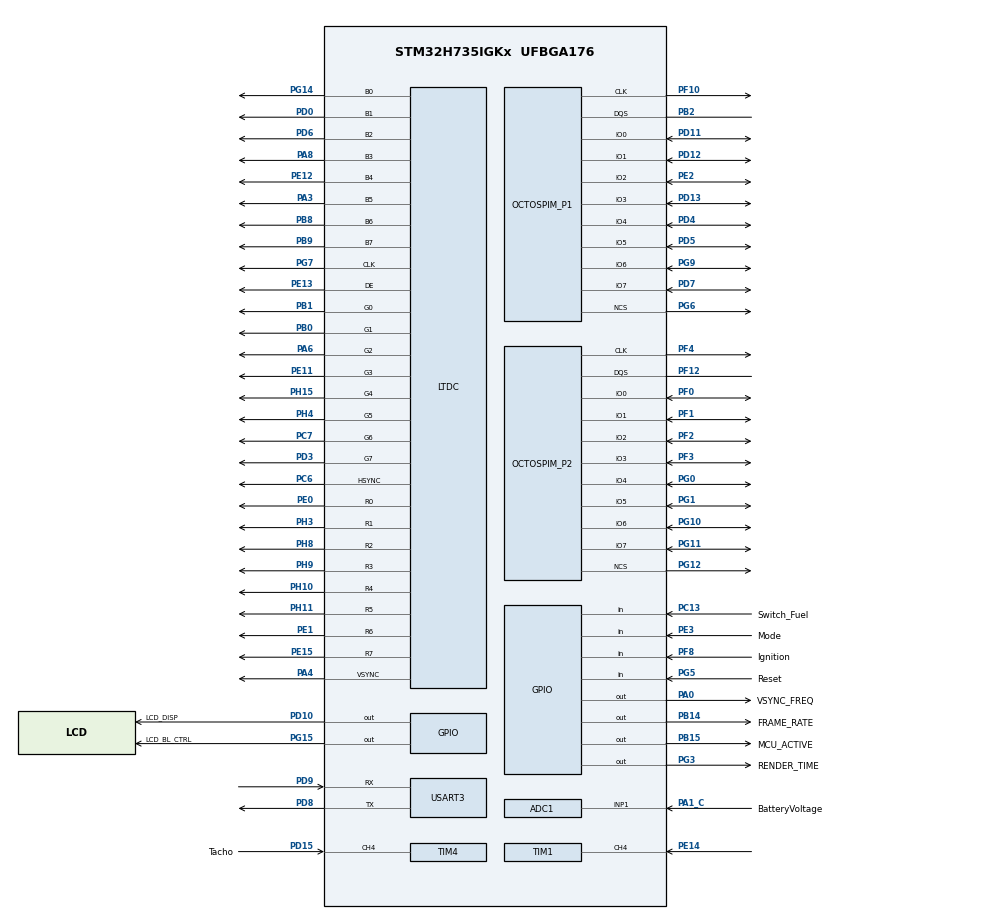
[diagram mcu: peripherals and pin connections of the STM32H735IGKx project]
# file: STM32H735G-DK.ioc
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ADC1.Channel-0\#ChannelRegularConversion=ADC_CHANNEL_1
ADC1.ClockPrescaler=ADC_CLOCK_SYNC_PCLK_DIV4
ADC1.NbrOfConversionFlag=1
ADC1.OffsetNumber-0\#ChannelRegularConversion=ADC_OFFSET_NONE
ADC1.OffsetSignedSaturation-0\#ChannelRegularConversion=DISABLE
ADC1.Rank-0\#ChannelRegularConversion=1
ADC1.Resolution=ADC_RESOLUTION_12B
ADC1.SamplingTime-0\#ChannelRegularConversion=ADC_SAMPLETIME_1CYCLE_5
ADC1.master=1
CORTEX_M7.AccessPermission-Cortex_Memory_Protection_Unit_Region0_Settings=MPU_REGION_FULL_ACCESS
CORTEX_M7.AccessPermission-Cortex_Memory_Protection_Unit_Region2_Settings=MPU_REGION_FULL_ACCESS
CORTEX_M7.AccessPermission-Cortex_Memory_Protection_Unit_Region4_Settings=MPU_REGION_FULL_ACCESS
CORTEX_M7.BaseAddress-Cortex_Memory_Protection_Unit_Region0_Settings=0x24000000
CORTEX_M7.BaseAddress-Cortex_Memory_Protection_Unit_Region1_Settings=0x70000000
CORTEX_M7.BaseAddress-Cortex_Memory_Protection_Unit_Region2_Settings=0x70000000
CORTEX_M7.BaseAddress-Cortex_Memory_Protection_Unit_Region3_Settings=0x90000000
CORTEX_M7.BaseAddress-Cortex_Memory_Protection_Unit_Region4_Settings=0x90000000
CORTEX_M7.CPU_DCache=Enabled
CORTEX_M7.CPU_ICache=Enabled
CORTEX_M7.DisableExec-Cortex_Memory_Protection_Unit_Region0_Settings=MPU_INSTRUCTION_ACCESS_DISABLE
CORTEX_M7.DisableExec-Cortex_Memory_Protection_Unit_Region1_Settings=MPU_INSTRUCTION_ACCESS_DISABLE
CORTEX_M7.DisableExec-Cortex_Memory_Protection_Unit_Region2_Settings=MPU_INSTRUCTION_ACCESS_DISABLE
CORTEX_M7.DisableExec-Cortex_Memory_Protection_Unit_Region3_Settings=MPU_INSTRUCTION_ACCESS_DISABLE
CORTEX_M7.DisableExec-Cortex_Memory_Protection_Unit_Region4_Settings=MPU_INSTRUCTION_ACCESS_DISABLE
CORTEX_M7.Enable-Cortex_Memory_Protection_Unit_Region0_Settings=MPU_REGION_ENABLE
CORTEX_M7.Enable-Cortex_Memory_Protection_Unit_Region1_Settings=MPU_REGION_ENABLE
CORTEX_M7.Enable-Cortex_Memory_Protection_Unit_Region2_Settings=MPU_REGION_ENABLE
CORTEX_M7.Enable-Cortex_Memory_Protection_Unit_Region3_Settings=MPU_REGION_ENABLE
CORTEX_M7.Enable-Cortex_Memory_Protection_Unit_Region4_Settings=MPU_REGION_ENABLE
CORTEX_M7.IsBufferable-Cortex_Memory_Protection_Unit_Region0_Settings=MPU_ACCESS_BUFFERABLE
CORTEX_M7.IsBufferable-Cortex_Memory_Protection_Unit_Region2_Settings=MPU_ACCESS_BUFFERABLE
CORTEX_M7.IsCacheable-Cortex_Memory_Protection_Unit_Region0_Settings=MPU_ACCESS_CACHEABLE
CORTEX_M7.IsCacheable-Cortex_Memory_Protection_Unit_Region2_Settings=MPU_ACCESS_CACHEABLE
CORTEX_M7.IsCacheable-Cortex_Memory_Protection_Unit_Region4_Settings=MPU_ACCESS_CACHEABLE
CORTEX_M7.MPU_Control=MPU_PRIVILEGED_DEFAULT
CORTEX_M7.Size-Cortex_Memory_Protection_Unit_Region0_Settings=MPU_REGION_SIZE_512KB
CORTEX_M7.Size-Cortex_Memory_Protection_Unit_Region1_Settings=MPU_REGION_SIZE_512MB
CORTEX_M7.Size-Cortex_Memory_Protection_Unit_Region2_Settings=MPU_REGION_SIZE_8MB
CORTEX_M7.Size-Cortex_Memory_Protection_Unit_Region3_Settings=MPU_REGION_SIZE_512MB
CORTEX_M7.Size-Cortex_Memory_Protection_Unit_Region4_Settings=MPU_REGION_SIZE_64MB
CORTEX_M7.default_mode_Activation=1
DMA2D.ColorMode=DMA2D_OUTPUT_RGB888
DMA2D.Mode=DMA2D_R2M
FREERTOS.Tasks01=defaultTask,24,128,StartDefaultTask,Default,NULL,Static,defaultTaskBuffer,defaultTaskControlBlock;TouchGFXTask,24,1024,TouchGFX_Task,As external,NULL,Dynamic,NULL,NULL;videoTask,8,1024,videoTaskFunc,As external,NULL,Static,videoTaskBuffer,videoTaskControlBlock;WatchdogService,8,128,WDG_SRVC_Task,Default,NULL,Static,WatchdogServiceBuffer,WatchdogServiceControlBlock;DigitalDebounce,8,128,DigitalDebounce_Task,Default,NULL,Static,DigitalDebounceBuffer,DigitalDebounceControlBlock;State_Manager,8,128,State_Machine,Default,NULL,Static,State_ManagerBuffer,State_ManagerControlBlock;Odometer,24,128,Odo_Task,Default,NULL,Static,OdometerBuffer,OdometerControlBlock;speedometer,24,128,speedo_Task,Default,NULL,Static,speedometerBuffer,speedometerControlBlock;Tachometer,24,128,Tacho_Task,Default,NULL,Static,TachometerBuffer,TachometerControlBlock
FREERTOS.configTOTAL_HEAP_SIZE=75000
FREERTOS.configUSE_APPLICATION_TASK_TAG=1
FREERTOS.configUSE_IDLE_HOOK=1
FREERTOS.configUSE_NEWLIB_REENTRANT=1
LIBJPEG.RGB_ORDERING=BGR
LTDC.ActiveH=272
LTDC.ActiveW=480
LTDC.Alpha_L0=255
LTDC.FBStartAdress_L0=0x70000000
LTDC.FBStartAdress_L1=0x70000000
LTDC.HBP=13
LTDC.HFP=32
LTDC.HSync=41
LTDC.ImageHeight_L0=272
LTDC.ImageWidth_L0=480
LTDC.Layers=0
LTDC.PixelFormat_L0=LTDC_PIXEL_FORMAT_RGB888
LTDC.VSync=10
LTDC.WindowX1_L0=480
LTDC.WindowY1_L0=272
Mcu.Family=STM32H7
Mcu.Name=STM32H735IGKx
Mcu.Package=UFBGA176
NVIC.DMA2D_IRQn=true\:5\:0\:true\:false\:true\:false\:true\:true\:true
NVIC.LTDC_IRQn=true\:5\:0\:true\:false\:true\:false\:true\:true\:true
NVIC.PriorityGroup=NVIC_PRIORITYGROUP_4
NVIC.TIM1_CC_IRQn=true\:5\:0\:false\:false\:true\:true\:true\:true\:true
NVIC.TIM4_IRQn=true\:5\:0\:false\:false\:true\:true\:true\:true\:true
NVIC.TIM6_DAC_IRQn=true\:0\:0\:false\:false\:true\:false\:false\:true\:true
NVIC.TimeBase=TIM6_DAC_IRQn
NVIC.TimeBaseIP=TIM6
OCTOSPI1.ChipSelectBoundary=0
OCTOSPI1.ChipSelectHighTime=2
OCTOSPI1.ClockPrescaler=2
OCTOSPI1.FifoThreshold=4
OCTOSPI1.MemoryType=HAL_OSPI_MEMTYPE_MACRONIX
OCTOSPI2.AccessTime=6
OCTOSPI2.ChipSelectBoundary=23
OCTOSPI2.ChipSelectHighTime=4
OCTOSPI2.ClkChipSelectHighTime=0
OCTOSPI2.ClockPrescaler=2
OCTOSPI2.DelayBlockBypass=HAL_OSPI_DELAY_BLOCK_USED
OCTOSPI2.DelayHoldQuarterCycle=HAL_OSPI_DHQC_ENABLE
OCTOSPI2.DeviceSize=24
OCTOSPI2.FifoThreshold=4
OCTOSPI2.LatencyMode=HAL_OSPI_FIXED_LATENCY
OCTOSPI2.RWRecoveryTime=3
OCTOSPI2.Refresh=400
OCTOSPI2.WriteZeroLatency=HAL_OSPI_LATENCY_ON_WRITE
PA0.GPIO_Label=VSYNC_FREQ
PA0.GPIO_Speed=GPIO_SPEED_FREQ_VERY_HIGH
PA0.Signal=GPIO_Output
PA1_C.GPIO_Label=BatteryVoltage
PA1_C.Signal=ADCx_INP1
PA3.GPIO_Speed=GPIO_SPEED_FREQ_VERY_HIGH
PA3.Mode=RGB888
PA3.Signal=LTDC_B5
PA4.GPIO_Speed=GPIO_SPEED_FREQ_VERY_HIGH
PA4.Mode=RGB888
PA4.Signal=LTDC_VSYNC
PA6.GPIO_Speed=GPIO_SPEED_FREQ_VERY_HIGH
PA6.Mode=RGB888
PA6.Signal=LTDC_G2
PA8.GPIO_Speed=GPIO_SPEED_FREQ_VERY_HIGH
PA8.Mode=RGB888
PA8.Signal=LTDC_B3
PB0.GPIO_Speed=GPIO_SPEED_FREQ_VERY_HIGH
PB0.Mode=RGB888
PB0.Signal=LTDC_G1
PB1.GPIO_Speed=GPIO_SPEED_FREQ_VERY_HIGH
PB1.Mode=RGB888
PB1.Signal=LTDC_G0
PB14.GPIO_Label=FRAME_RATE
PB14.GPIO_Speed=GPIO_SPEED_FREQ_VERY_HIGH
PB14.Signal=GPIO_Output
PB15.GPIO_Label=MCU_ACTIVE
PB15.GPIO_Speed=GPIO_SPEED_FREQ_VERY_HIGH
PB15.Signal=GPIO_Output
PB2.Mode=OCTOSPI1_Port1_DQS
PB2.Signal=OCTOSPIM_P1_DQS
PB8.GPIO_Speed=GPIO_SPEED_FREQ_VERY_HIGH
PB8.Mode=RGB888
PB8.Signal=LTDC_B6
PB9.GPIO_Speed=GPIO_SPEED_FREQ_VERY_HIGH
PB9.Mode=RGB888
PB9.Signal=LTDC_B7
PC13.GPIO_Label=Switch_Fuel
PC13.GPIO_PuPd=GPIO_PULLDOWN
PC13.Signal=GPIO_Input
PC6.GPIO_Speed=GPIO_SPEED_FREQ_VERY_HIGH
PC6.Mode=RGB888
PC6.Signal=LTDC_HSYNC
PC7.GPIO_Speed=GPIO_SPEED_FREQ_VERY_HIGH
PC7.Mode=RGB888
PC7.Signal=LTDC_G6
PD0.GPIO_Speed=GPIO_SPEED_FREQ_VERY_HIGH
PD0.Mode=RGB888
PD0.Signal=LTDC_B1
PD10.GPIO_Label=LCD_DISP
PD10.GPIO_PuPd=GPIO_NOPULL
PD10.GPIO_Speed=GPIO_SPEED_FREQ_LOW
PD10.PinState=GPIO_PIN_RESET
PD10.Signal=GPIO_Output
PD11.Mode=OCTOSPI1_IOL_Port1L
PD11.Signal=OCTOSPIM_P1_IO0
PD12.Mode=OCTOSPI1_IOL_Port1L
PD12.Signal=OCTOSPIM_P1_IO1
PD13.Mode=OCTOSPI1_IOL_Port1L
PD13.Signal=OCTOSPIM_P1_IO3
PD15.GPIO_Label=Tacho
PD15.Signal=S_TIM4_CH4
PD3.GPIO_Speed=GPIO_SPEED_FREQ_VERY_HIGH
PD3.Mode=RGB888
PD3.Signal=LTDC_G7
PD4.Mode=OCTOSPI1_IOH_Port1H
PD4.Signal=OCTOSPIM_P1_IO4
PD5.Mode=OCTOSPI1_IOH_Port1H
PD5.Signal=OCTOSPIM_P1_IO5
PD6.GPIO_Speed=GPIO_SPEED_FREQ_VERY_HIGH
PD6.Mode=RGB888
PD6.Signal=LTDC_B2
PD7.Mode=OCTOSPI1_IOH_Port1H
PD7.Signal=OCTOSPIM_P1_IO7
PD8.Mode=Asynchronous
PD8.Signal=USART3_TX
PD9.Mode=Asynchronous
PD9.Signal=USART3_RX
PE0.GPIO_Speed=GPIO_SPEED_FREQ_VERY_HIGH
PE0.Mode=RGB888
PE0.Signal=LTDC_R0
PE1.GPIO_Speed=GPIO_SPEED_FREQ_VERY_HIGH
PE1.Mode=RGB888
PE1.Signal=LTDC_R6
PE11.GPIO_Speed=GPIO_SPEED_FREQ_VERY_HIGH
PE11.Mode=RGB888
PE11.Signal=LTDC_G3
PE12.GPIO_Speed=GPIO_SPEED_FREQ_VERY_HIGH
PE12.Mode=RGB888
PE12.Signal=LTDC_B4
PE13.GPIO_Speed=GPIO_SPEED_FREQ_VERY_HIGH
PE13.Mode=RGB888
PE13.Signal=LTDC_DE
PE14.GPIO_PuPd=GPIO_PULLDOWN
PE14.Signal=S_TIM1_CH4
PE15.GPIO_Speed=GPIO_SPEED_FREQ_VERY_HIGH
PE15.Mode=RGB888
PE15.Signal=LTDC_R7
PE2.Mode=OCTOSPI1_IOL_Port1L
PE2.Signal=OCTOSPIM_P1_IO2
PE3.GPIO_Label=Mode
PE3.GPIO_PuPd=GPIO_PULLUP
PE3.Signal=GPIO_Input
PF0.Mode=OCTOSPI2_IOL_Port2L
PF0.Signal=OCTOSPIM_P2_IO0
PF1.Mode=OCTOSPI2_IOL_Port2L
PF1.Signal=OCTOSPIM_P2_IO1
PF10.Mode=O1_P1_CLK
PF10.Signal=OCTOSPIM_P1_CLK
PF12.Mode=OCTOSPI2_Port2_DQS
PF12.Signal=OCTOSPIM_P2_DQS
PF2.Mode=OCTOSPI2_IOL_Port2L
PF2.Signal=OCTOSPIM_P2_IO2
PF3.Mode=OCTOSPI2_IOL_Port2L
PF3.Signal=OCTOSPIM_P2_IO3
PF4.Mode=O2_P2_CLK
PF4.Signal=OCTOSPIM_P2_CLK
PF6.Signal=FDCAN3_RX
PF8.GPIO_Label=Ignition
PF8.GPIO_PuPd=GPIO_PULLUP
PF8.Signal=GPIO_Input
PG0.Mode=OCTOSPI2_IOH_Port2H
PG0.Signal=OCTOSPIM_P2_IO4
PG1.Mode=OCTOSPI2_IOH_Port2H
PG1.Signal=OCTOSPIM_P2_IO5
PG10.Mode=OCTOSPI2_IOH_Port2H
PG10.Signal=OCTOSPIM_P2_IO6
PG11.Mode=OCTOSPI2_IOH_Port2H
PG11.Signal=OCTOSPIM_P2_IO7
PG12.Mode=OCTOSPI2_Port2_NCS
PG12.Signal=OCTOSPIM_P2_NCS
PG14.GPIO_Speed=GPIO_SPEED_FREQ_VERY_HIGH
PG14.Mode=RGB888
PG14.Signal=LTDC_B0
PG15.GPIO_Label=LCD_BL_CTRL
PG15.Signal=GPIO_Output
PG3.GPIO_Label=RENDER_TIME
PG3.GPIO_Speed=GPIO_SPEED_FREQ_VERY_HIGH
PG3.Signal=GPIO_Output
PG5.GPIO_Label=Reset
PG5.GPIO_PuPd=GPIO_PULLUP
PG5.Signal=GPIO_Input
PG6.Mode=OCTOSPI1_Port1_NCS
PG6.Signal=OCTOSPIM_P1_NCS
PG7.GPIO_Speed=GPIO_SPEED_FREQ_VERY_HIGH
PG7.Mode=RGB888
PG7.Signal=LTDC_CLK
PG9.Mode=OCTOSPI1_IOH_Port1H
PG9.Signal=OCTOSPIM_P1_IO6
PH0-OSC_IN.Mode=HSE-External-Oscillator
PH0-OSC_IN.Signal=RCC_OSC_IN
PH1-OSC_OUT.Mode=HSE-External-Oscillator
PH1-OSC_OUT.Signal=RCC_OSC_OUT
PH10.GPIO_Speed=GPIO_SPEED_FREQ_VERY_HIGH
PH10.Mode=RGB888
PH10.Signal=LTDC_R4
PH11.GPIO_Speed=GPIO_SPEED_FREQ_VERY_HIGH
PH11.Mode=RGB888
PH11.Signal=LTDC_R5
PH15.GPIO_Speed=GPIO_SPEED_FREQ_VERY_HIGH
PH15.Mode=RGB888
PH15.Signal=LTDC_G4
PH3.GPIO_Speed=GPIO_SPEED_FREQ_VERY_HIGH
PH3.Mode=RGB888
PH3.Signal=LTDC_R1
PH4.GPIO_Speed=GPIO_SPEED_FREQ_VERY_HIGH
PH4.Mode=RGB888
PH4.Signal=LTDC_G5
PH8.GPIO_Speed=GPIO_SPEED_FREQ_VERY_HIGH
PH8.Mode=RGB888
PH8.Signal=LTDC_R2
PH9.GPIO_Speed=GPIO_SPEED_FREQ_VERY_HIGH
PH9.Mode=RGB888
PH9.Signal=LTDC_R3
ProjectManager.HeapSize=0x1000
ProjectManager.StackSize=0x1000
ProjectManager.TargetToolchain=STM32CubeIDE
RCC.ADCFreq_Value=200000000
RCC.APB1Freq_Value=137500000
RCC.APB2Freq_Value=137500000
RCC.APB3Freq_Value=137500000
RCC.APB4Freq_Value=137500000
RCC.CortexFreq_Value=550000000
RCC.D1PPRE=RCC_APB3_DIV2
RCC.D2PPRE1=RCC_APB1_DIV2
RCC.D2PPRE2=RCC_APB2_DIV2
RCC.D3PPRE=RCC_APB4_DIV2
RCC.DIVM1=2
RCC.DIVM2=5
RCC.DIVM3=25
RCC.DIVN1=44
RCC.DIVN2=80
RCC.DIVN3=288
RCC.DIVP1=1
RCC.DIVR3=30
RCC.HCLKFreq_Value=275000000
RCC.HPRE=RCC_HCLK_DIV2
RCC.PLL2FRACN=0
RCC.PLLFRACN=0
RCC.PLLSourceVirtual=RCC_PLLSOURCE_HSE
RCC.QSPICLockSelection=RCC_OSPICLKSOURCE_PLL2
RCC.SYSCLKFreq_VALUE=550000000
RCC.SYSCLKSource=RCC_SYSCLKSOURCE_PLLCLK
RCC.SupplySource=PWR_DIRECT_SMPS_SUPPLY
RCC.USBFreq_Value=275000000
SH.ADCx_INP1.0=ADC1_INP1,IN1-Single-Ended
SH.S_TIM1_CH4.0=TIM1_CH4,Input_Capture4_from_TI4
SH.S_TIM4_CH4.0=TIM4_CH4,Input_Capture4_from_TI4
STMicroelectronics.X-CUBE-TOUCHGFX.4.23.1.ApplicationCcGraphicsJjApplication=TouchGFXOoGenerator
STMicroelectronics.X-CUBE-TOUCHGFX.4.23.1.tgfx_address1=0x70000000
STMicroelectronics.X-CUBE-TOUCHGFX.4.23.1.tgfx_address2=0x70060000
STMicroelectronics.X-CUBE-TOUCHGFX.4.23.1.tgfx_buffering_strategy=Double
STMicroelectronics.X-CUBE-TOUCHGFX.4.23.1.tgfx_display_interface=disp_ltdc
STMicroelectronics.X-CUBE-TOUCHGFX.4.23.1.tgfx_hardware_accelerator=dma_2d
STMicroelectronics.X-CUBE-TOUCHGFX.4.23.1.tgfx_location=Allocate
STMicroelectronics.X-CUBE-TOUCHGFX.4.23.1.tgfx_vector_fonts=Enabled
STMicroelectronics.X-CUBE-TOUCHGFX.4.23.1.tgfx_vector_rendering=Software
STMicroelectronics.X-CUBE-TOUCHGFX.4.23.1.tgfx_video=Software
STMicroelectronics.X-CUBE-TOUCHGFX.4.23.1.tgfx_video_buffer_format=RGB888\:3
STMicroelectronics.X-CUBE-TOUCHGFX.4.23.1.tgfx_video_height=272
STMicroelectronics.X-CUBE-TOUCHGFX.4.23.1.tgfx_video_strategy=1
STMicroelectronics.X-CUBE-TOUCHGFX.4.23.1.tgfx_video_width=480
STMicroelectronics.X-CUBE-TOUCHGFX.4.23.1.tgfx_vsync=vsync_ltdc
TIM1.Channel-Input_Capture4_from_TI4=TIM_CHANNEL_4
TIM4.Channel-Input_Capture4_from_TI4=TIM_CHANNEL_4
USART3.Parity=PARITY_NONE
USART3.VirtualMode-Asynchronous=VM_ASYNC
VP_CRC_VS_CRC.Mode=CRC_Activate
VP_DMA2D_VS_DMA2D.Mode=DMA2D_Activate
VP_FREERTOS_VS_CMSIS_V2.Mode=CMSIS_V2
VP_LIBJPEG_VS_JPEGLIB.Mode=Enabled
VP_OCTOSPI1_VS_octo.Mode=octo_mode
VP_OCTOSPI2_VS_octo.Mode=hyperbus_mode
VP_RTC_VS_RTC_Activate.Mode=RTC_Enabled
VP_RTC_VS_RTC_Calendar.Mode=RTC_Calendar
VP_STMicroelectronics.X-CUBE-TOUCHGFX_VS_GraphicsJjApplication_4.23.1.Mode=GraphicsJjApplication
VP_SYS_VS_tim6.Mode=TIM6
VP_TIM1_VS_ClockSourceINT.Mode=Internal
VP_WWDG1_VS_WWDG.Mode=WWDG_Activate
WWDG1.Counter=0x7F
WWDG1.Prescaler=WWDG_PRESCALER_128
WWDG1.Window=0x50
board=custom

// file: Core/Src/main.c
/* USER CODE BEGIN Header */
/**
  ******************************************************************************
  * @file           : main.c
  * @brief          : Main program body
  ******************************************************************************
  * @attention
  *
  * <h2><center>&copy; Copyright (c) 2020 STMicroelectronics.
  * All rights reserved.</center></h2>
  *
  * This software component is licensed by ST under Ultimate Liberty license
  * SLA0044, the "License"; You may not use this file except in compliance with
  * the License. You may obtain a copy of the License at:
  *                             www.st.com/SLA0044
  *
  ******************************************************************************
  */
/* USER CODE END Header */
#include "main.h"
#include "cmsis_os.h"
#include "libjpeg.h"
#include "app_touchgfx.h"

/* USER CODE BEGIN Includes */
#include "stm32h735g_discovery_ospi.h"
#include "stm32h7xx_hal_ospi.h"
#include "smHandler.h"
#include "digital_debounce.h"
#include "Tachometer_App.h"
#include "Odometer_App.h"
#include "speedometer_App.h"
#include "eeprom_emul.h"
#include <touchgfx/hal/Config.hpp>

/* USER CODE END Includes */

typedef StaticTask_t osStaticThreadDef_t;
/* USER CODE BEGIN PTD */
#ifdef __GNUC__
/* With GCC, small printf (option LD Linker->Libraries->Small printf
   set to 'Yes') calls __io_putchar() */
#define PUTCHAR_PROTOTYPE int __io_putchar(int ch)
#else
#define PUTCHAR_PROTOTYPE int fputc(int ch, FILE *f)
#endif /* __GNUC__ */
/* USER CODE END PTD */

ADC_HandleTypeDef hadc1;

CRC_HandleTypeDef hcrc;

DMA2D_HandleTypeDef hdma2d;

LTDC_HandleTypeDef hltdc;

OSPI_HandleTypeDef hospi1;
OSPI_HandleTypeDef hospi2;

RTC_HandleTypeDef hrtc;

TIM_HandleTypeDef htim1;
TIM_HandleTypeDef htim4;

UART_HandleTypeDef huart3;

WWDG_HandleTypeDef hwwdg1;

/* Definitions for defaultTask */
osThreadId_t defaultTaskHandle;
uint32_t defaultTaskBuffer[ 128 ];
osStaticThreadDef_t defaultTaskControlBlock;
const osThreadAttr_t defaultTask_attributes = {
  .name = "defaultTask",
  .cb_mem = &defaultTaskControlBlock,
  .cb_size = sizeof(defaultTaskControlBlock),
  .stack_mem = &defaultTaskBuffer[0],
  .stack_size = sizeof(defaultTaskBuffer),
  .priority = (osPriority_t) osPriorityNormal,
};
/* Definitions for TouchGFXTask */
osThreadId_t TouchGFXTaskHandle;
const osThreadAttr_t TouchGFXTask_attributes = {
  .name = "TouchGFXTask",
  .stack_size = 1024 * 4,
  .priority = (osPriority_t) osPriorityNormal,
};
/* Definitions for videoTask */
osThreadId_t videoTaskHandle;
uint32_t videoTaskBuffer[ 1024 ];
osStaticThreadDef_t videoTaskControlBlock;
const osThreadAttr_t videoTask_attributes = {
  .name = "videoTask",
  .cb_mem = &videoTaskControlBlock,
  .cb_size = sizeof(videoTaskControlBlock),
  .stack_mem = &videoTaskBuffer[0],
  .stack_size = sizeof(videoTaskBuffer),
  .priority = (osPriority_t) osPriorityLow,
};
/* Definitions for WatchdogService */
osThreadId_t WatchdogServiceHandle;
uint32_t WatchdogServiceBuffer[ 128 ];
osStaticThreadDef_t WatchdogServiceControlBlock;
const osThreadAttr_t WatchdogService_attributes = {
  .name = "WatchdogService",
  .cb_mem = &WatchdogServiceControlBlock,
  .cb_size = sizeof(WatchdogServiceControlBlock),
  .stack_mem = &WatchdogServiceBuffer[0],
  .stack_size = sizeof(WatchdogServiceBuffer),
  .priority = (osPriority_t) osPriorityLow,
};
/* Definitions for DigitalDebounce */
osThreadId_t DigitalDebounceHandle;
uint32_t DigitalDebounceBuffer[ 4096*2 ];
osStaticThreadDef_t DigitalDebounceControlBlock;
const osThreadAttr_t DigitalDebounce_attributes = {
  .name = "DigitalDebounce",
  .cb_mem = &DigitalDebounceControlBlock,
  .cb_size = sizeof(DigitalDebounceControlBlock),
  .stack_mem = &DigitalDebounceBuffer[0],
  .stack_size = sizeof(DigitalDebounceBuffer),
  .priority = (osPriority_t) osPriorityNormal,
};
/* Definitions for State_Manager */
osThreadId_t State_ManagerHandle;
uint32_t State_ManagerBuffer[ 128 ];
osStaticThreadDef_t State_ManagerControlBlock;
const osThreadAttr_t State_Manager_attributes = {
  .name = "State_Manager",
  .cb_mem = &State_ManagerControlBlock,
  .cb_size = sizeof(State_ManagerControlBlock),
  .stack_mem = &State_ManagerBuffer[0],
  .stack_size = sizeof(State_ManagerBuffer),
  .priority = (osPriority_t) osPriorityLow,
};
/* Definitions for Odometer */
osThreadId_t OdometerHandle;
uint32_t OdometerBuffer[ 128 ];
osStaticThreadDef_t OdometerControlBlock;
const osThreadAttr_t Odometer_attributes = {
  .name = "Odometer",
  .cb_mem = &OdometerControlBlock,
  .cb_size = sizeof(OdometerControlBlock),
  .stack_mem = &OdometerBuffer[0],
  .stack_size = sizeof(OdometerBuffer),
  .priority = (osPriority_t) osPriorityNormal,
};
/* Definitions for speedometer */
osThreadId_t speedometerHandle;
uint32_t speedometerBuffer[ 128 ];
osStaticThreadDef_t speedometerControlBlock;
const osThreadAttr_t speedometer_attributes = {
  .name = "speedometer",
  .cb_mem = &speedometerControlBlock,
  .cb_size = sizeof(speedometerControlBlock),
  .stack_mem = &speedometerBuffer[0],
  .stack_size = sizeof(speedometerBuffer),
  .priority = (osPriority_t) osPriorityNormal,
};
/* Definitions for Tachometer */
osThreadId_t TachometerHandle;
uint32_t TachometerBuffer[ 128 ];
osStaticThreadDef_t TachometerControlBlock;
const osThreadAttr_t Tachometer_attributes = {
  .name = "Tachometer",
  .cb_mem = &TachometerControlBlock,
  .cb_size = sizeof(TachometerControlBlock),
  .stack_mem = &TachometerBuffer[0],
  .stack_size = sizeof(TachometerBuffer),
  .priority = (osPriority_t) osPriorityNormal,
};
/* USER CODE BEGIN PV */
/**
  * @brief  Retargets the C library printf function to the USART.
  * @param  None
  * @retval None
  */
PUTCHAR_PROTOTYPE
{
  /* Place your implementation of fputc here */
  /* e.g. write a character to the USART1 and Loop until the end of transmission */
  HAL_UART_Transmit(&huart3, (uint8_t *)&ch, 1, 0xFFFF);
  return ch;
}
/* USER CODE END PV */

void SystemClock_Config(void);
void PeriphCommonClock_Config(void);
static void MPU_Config(void);
static void MX_GPIO_Init(void);
static void MX_CRC_Init(void);
static void MX_DMA2D_Init(void);
static void MX_LTDC_Init(void);
static void MX_OCTOSPI1_Init(void);
static void MX_OCTOSPI2_Init(void);
static void MX_TIM1_Init(void);
static void MX_TIM4_Init(void);
static void MX_ADC1_Init(void);
static void MX_RTC_Init(void);
static void MX_WWDG1_Init(void);
static void MX_USART3_UART_Init(void);
void StartDefaultTask(void *argument);
extern void TouchGFX_Task(void *argument);
extern void videoTaskFunc(void *argument);
void WDG_SRVC_Task(void *argument);
void DigitalDebounce_Task(void *argument);
void State_Machine(void *argument);
void Odo_Task(void *argument);
void speedo_Task(void *argument);
void Tacho_Task(void *argument);

/* USER CODE BEGIN PFP */
static uint32_t TimeoutCalculation(uint32_t timevalue);
extern void vEE_Demo(void);
void Disp_imgDataHyperRAM_Init(void);
/* USER CODE END PFP */

/* USER CODE BEGIN 0 */
KEEP extern const unsigned char image_image_const[];
KEEP extern const unsigned char image_fuel_red_const[];
extern unsigned char ucImage_image_HypRam[(32640*12)];
extern unsigned char ucImage_fuel_red_HypRAM[160*12];

/* USER CODE END 0 */

int main(void)
{

  /* MPU Configuration--------------------------------------------------------*/
  MPU_Config();

  /* Enable the CPU Cache */

  /* Enable I-Cache---------------------------------------------------------*/
  SCB_EnableICache();

  /* Enable D-Cache---------------------------------------------------------*/
  SCB_EnableDCache();

  /* MCU Configuration--------------------------------------------------------*/

  /* Reset of all peripherals, Initializes the Flash interface and the Systick. */
  HAL_Init();

  /* Configure the system clock */
  SystemClock_Config();

/* Configure the peripherals common clocks */
  PeriphCommonClock_Config();

  /* Initialize all configured peripherals */

  MX_GPIO_Init();
  MX_CRC_Init();
  MX_DMA2D_Init();
  MX_LTDC_Init();
//  MX_OCTOSPI1_Init();
  MX_OCTOSPI2_Init();
  MX_LIBJPEG_Init();
  MX_TIM1_Init();
  MX_TIM4_Init();
  MX_ADC1_Init();
  MX_RTC_Init();
//  MX_WWDG1_Init();
  MX_USART3_UART_Init();
  MX_TouchGFX_Init();
  /* Call PreOsInit function */
  MX_TouchGFX_PreOSInit();

  /* USER CODE BEGIN 2 */

  State_Manager_init();
  vOdoInit();
  vSpeedoInit();

  if(HAL_TIM_IC_Start_IT(&htim1,TIM_CHANNEL_4)!=HAL_OK)
  {
	  Error_Handler();
  }
  if(HAL_TIM_IC_Start_IT(&htim4,TIM_CHANNEL_4)!=HAL_OK)
  {
	  Error_Handler();
  }

  vEE_Demo();
  Disp_imgDataHyperRAM_Init();

  /* USER CODE END 2 */

  /* Init scheduler */
  osKernelInitialize();

  /* Create the thread(s) */
  /* creation of defaultTask */
  defaultTaskHandle = osThreadNew(StartDefaultTask, NULL, &defaultTask_attributes);

  /* creation of TouchGFXTask */
  TouchGFXTaskHandle = osThreadNew(TouchGFX_Task, NULL, &TouchGFXTask_attributes);

  /* creation of videoTask */
  videoTaskHandle = osThreadNew(videoTaskFunc, NULL, &videoTask_attributes);

  /* creation of WatchdogService */
  WatchdogServiceHandle = osThreadNew(WDG_SRVC_Task, NULL, &WatchdogService_attributes);

  /* creation of DigitalDebounce */
  DigitalDebounceHandle = osThreadNew(DigitalDebounce_Task, NULL, &DigitalDebounce_attributes);

  /* creation of State_Manager */
  State_ManagerHandle = osThreadNew(State_Machine, NULL, &State_Manager_attributes);

  /* creation of Odometer */
  OdometerHandle = osThreadNew(Odo_Task, NULL, &Odometer_attributes);

  /* creation of speedometer */
  speedometerHandle = osThreadNew(speedo_Task, NULL, &speedometer_attributes);

  /* creation of Tachometer */
  TachometerHandle = osThreadNew(Tacho_Task, NULL, &Tachometer_attributes);

  /* Start scheduler */
  osKernelStart();

  /* We should never get here as control is now taken by the scheduler */

  /* Infinite loop */
  while (1)
  {

  }
}

void SystemClock_Config(void)
{
  RCC_OscInitTypeDef RCC_OscInitStruct = {0};
  RCC_ClkInitTypeDef RCC_ClkInitStruct = {0};

  /** Supply configuration update enable
  */
  HAL_PWREx_ConfigSupply(PWR_DIRECT_SMPS_SUPPLY);

  /** Configure the main internal regulator output voltage
  */
  __HAL_PWR_VOLTAGESCALING_CONFIG(PWR_REGULATOR_VOLTAGE_SCALE0);

  while(!__HAL_PWR_GET_FLAG(PWR_FLAG_VOSRDY)) {}
#if 0
  /** Initializes the RCC Oscillators according to the specified parameters
  * in the RCC_OscInitTypeDef structure.
  */
  RCC_OscInitStruct.OscillatorType = RCC_OSCILLATORTYPE_LSI|RCC_OSCILLATORTYPE_HSE;
  RCC_OscInitStruct.HSEState = RCC_HSE_ON;
  RCC_OscInitStruct.LSIState = RCC_LSI_ON;
  RCC_OscInitStruct.PLL.PLLState = RCC_PLL_ON;
  RCC_OscInitStruct.PLL.PLLSource = RCC_PLLSOURCE_HSE;
  RCC_OscInitStruct.PLL.PLLM = 2;
  RCC_OscInitStruct.PLL.PLLN = 44;
  RCC_OscInitStruct.PLL.PLLP = 1;
  RCC_OscInitStruct.PLL.PLLQ = 2;
  RCC_OscInitStruct.PLL.PLLR = 2;
  RCC_OscInitStruct.PLL.PLLRGE = RCC_PLL1VCIRANGE_3;
  RCC_OscInitStruct.PLL.PLLVCOSEL = RCC_PLL1VCOWIDE;
  RCC_OscInitStruct.PLL.PLLFRACN = 0;
  if (HAL_RCC_OscConfig(&RCC_OscInitStruct) != HAL_OK)
  {
    Error_Handler();
  }

  /** Initializes the CPU, AHB and APB buses clocks
  */
  RCC_ClkInitStruct.ClockType = RCC_CLOCKTYPE_HCLK|RCC_CLOCKTYPE_SYSCLK
                              |RCC_CLOCKTYPE_PCLK1|RCC_CLOCKTYPE_PCLK2
                              |RCC_CLOCKTYPE_D3PCLK1|RCC_CLOCKTYPE_D1PCLK1;
  RCC_ClkInitStruct.SYSCLKSource = RCC_SYSCLKSOURCE_PLLCLK;
  RCC_ClkInitStruct.SYSCLKDivider = RCC_SYSCLK_DIV1;
  RCC_ClkInitStruct.AHBCLKDivider = RCC_HCLK_DIV2;
  RCC_ClkInitStruct.APB3CLKDivider = RCC_APB3_DIV2;
  RCC_ClkInitStruct.APB1CLKDivider = RCC_APB1_DIV2;
  RCC_ClkInitStruct.APB2CLKDivider = RCC_APB2_DIV2;
  RCC_ClkInitStruct.APB4CLKDivider = RCC_APB4_DIV2;

  if (HAL_RCC_ClockConfig(&RCC_ClkInitStruct, FLASH_LATENCY_3) != HAL_OK)
  {
    Error_Handler();
  }
#endif
  /** Initializes the RCC Oscillators according to the specified parameters
  * in the RCC_OscInitTypeDef structure.
  */
  RCC_OscInitStruct.OscillatorType = RCC_OSCILLATORTYPE_HSE;
  RCC_OscInitStruct.HSEState = RCC_HSE_ON;
  RCC_OscInitStruct.PLL.PLLState = RCC_PLL_ON;
  RCC_OscInitStruct.PLL.PLLSource = RCC_PLLSOURCE_HSE;
  RCC_OscInitStruct.PLL.PLLM = 5;
  RCC_OscInitStruct.PLL.PLLN = 104;
  RCC_OscInitStruct.PLL.PLLP = 1;
  RCC_OscInitStruct.PLL.PLLQ = 4;
  RCC_OscInitStruct.PLL.PLLR = 2;
  RCC_OscInitStruct.PLL.PLLRGE = RCC_PLL1VCIRANGE_2;
  RCC_OscInitStruct.PLL.PLLVCOSEL = RCC_PLL1VCOWIDE;
  RCC_OscInitStruct.PLL.PLLFRACN = 0;
  if (HAL_RCC_OscConfig(&RCC_OscInitStruct) != HAL_OK)
  {
    Error_Handler();
  }

  /** Initializes the CPU, AHB and APB buses clocks
  */
  RCC_ClkInitStruct.ClockType = RCC_CLOCKTYPE_HCLK|RCC_CLOCKTYPE_SYSCLK
                              |RCC_CLOCKTYPE_PCLK1|RCC_CLOCKTYPE_PCLK2
                              |RCC_CLOCKTYPE_D3PCLK1|RCC_CLOCKTYPE_D1PCLK1;
  RCC_ClkInitStruct.SYSCLKSource = RCC_SYSCLKSOURCE_PLLCLK;
  RCC_ClkInitStruct.SYSCLKDivider = RCC_SYSCLK_DIV1;
  RCC_ClkInitStruct.AHBCLKDivider = RCC_HCLK_DIV2;
  RCC_ClkInitStruct.APB3CLKDivider = RCC_APB3_DIV2;
  RCC_ClkInitStruct.APB1CLKDivider = RCC_APB1_DIV2;
  RCC_ClkInitStruct.APB2CLKDivider = RCC_APB2_DIV2;
  RCC_ClkInitStruct.APB4CLKDivider = RCC_APB4_DIV2;

  if (HAL_RCC_ClockConfig(&RCC_ClkInitStruct, FLASH_LATENCY_3) != HAL_OK)
  {
    Error_Handler();
  }

}

void PeriphCommonClock_Config(void)
{
#if 0
  RCC_PeriphCLKInitTypeDef PeriphClkInitStruct = {0};

  /** Initializes the peripherals clock
  */
  PeriphClkInitStruct.PeriphClockSelection = RCC_PERIPHCLK_OSPI;
  PeriphClkInitStruct.PLL2.PLL2M = 5;
  PeriphClkInitStruct.PLL2.PLL2N = 80;
  PeriphClkInitStruct.PLL2.PLL2P = 2;
  PeriphClkInitStruct.PLL2.PLL2Q = 2;
  PeriphClkInitStruct.PLL2.PLL2R = 2;
  PeriphClkInitStruct.PLL2.PLL2RGE = RCC_PLL2VCIRANGE_2;
  PeriphClkInitStruct.PLL2.PLL2VCOSEL = RCC_PLL2VCOWIDE;
  PeriphClkInitStruct.PLL2.PLL2FRACN = 0;
  PeriphClkInitStruct.OspiClockSelection = RCC_OSPICLKSOURCE_PLL2;
#endif
  RCC_PeriphCLKInitTypeDef  PeriphClkInitStruct;

  /* HyperRAM clock configuration */
  /* OSPI clock configuration */
  /* PLL2_VCO Input = HSE_VALUE/PLL3M = 5 Mhz */
  /* PLL2_VCO Output = PLL2_VCO Input * PLL3N = 400 Mhz */
  /* PLLOSPICLK = PLL2_VCO Output/PLL2R = 400/2 = 200 Mhz */
  /* OSPI clock frequency = PLLOSPICLK = 200 Mhz */
  PeriphClkInitStruct.PeriphClockSelection = RCC_PERIPHCLK_OSPI ;
  PeriphClkInitStruct.OspiClockSelection = RCC_OSPICLKSOURCE_PLL2;
  PeriphClkInitStruct.PLL2.PLL2M = 5;
  PeriphClkInitStruct.PLL2.PLL2N = 80;
  PeriphClkInitStruct.PLL2.PLL2P = 5;
  PeriphClkInitStruct.PLL2.PLL2Q = 2;
  PeriphClkInitStruct.PLL2.PLL2R = 2;
  PeriphClkInitStruct.PLL2.PLL2FRACN = 0;
  PeriphClkInitStruct.PLL2.PLL2VCOSEL = RCC_PLL2VCOWIDE;
  PeriphClkInitStruct.PLL2.PLL2RGE = RCC_PLL2VCIRANGE_0;
  if (HAL_RCCEx_PeriphCLKConfig(&PeriphClkInitStruct) != HAL_OK)
  {
    Error_Handler();
  }
}

static void MX_ADC1_Init(void)
{

  ADC_MultiModeTypeDef multimode = {0};
  ADC_ChannelConfTypeDef sConfig = {0};

  /** Common config
  */
  hadc1.Instance = ADC1;
  hadc1.Init.ClockPrescaler = ADC_CLOCK_SYNC_PCLK_DIV4;
  hadc1.Init.Resolution = ADC_RESOLUTION_12B;
  hadc1.Init.ScanConvMode = ADC_SCAN_DISABLE;
  hadc1.Init.EOCSelection = ADC_EOC_SINGLE_CONV;
  hadc1.Init.LowPowerAutoWait = DISABLE;
  hadc1.Init.ContinuousConvMode = DISABLE;
  hadc1.Init.NbrOfConversion = 1;
  hadc1.Init.DiscontinuousConvMode = DISABLE;
  hadc1.Init.ExternalTrigConv = ADC_SOFTWARE_START;
  hadc1.Init.ExternalTrigConvEdge = ADC_EXTERNALTRIGCONVEDGE_NONE;
  hadc1.Init.ConversionDataManagement = ADC_CONVERSIONDATA_DR;
  hadc1.Init.Overrun = ADC_OVR_DATA_PRESERVED;
  hadc1.Init.LeftBitShift = ADC_LEFTBITSHIFT_NONE;
  hadc1.Init.OversamplingMode = DISABLE;
  if (HAL_ADC_Init(&hadc1) != HAL_OK)
  {
    Error_Handler();
  }

  /** Configure the ADC multi-mode
  */
  multimode.Mode = ADC_MODE_INDEPENDENT;
  if (HAL_ADCEx_MultiModeConfigChannel(&hadc1, &multimode) != HAL_OK)
  {
    Error_Handler();
  }

  /** Configure Regular Channel
  */
  sConfig.Channel = ADC_CHANNEL_1;
  sConfig.Rank = ADC_REGULAR_RANK_1;
  sConfig.SamplingTime = ADC_SAMPLETIME_1CYCLE_5;
  sConfig.SingleDiff = ADC_SINGLE_ENDED;
  sConfig.OffsetNumber = ADC_OFFSET_NONE;
  sConfig.Offset = 0;
  sConfig.OffsetSignedSaturation = DISABLE;
  if (HAL_ADC_ConfigChannel(&hadc1, &sConfig) != HAL_OK)
  {
    Error_Handler();
  }

}

static void MX_CRC_Init(void)
{

  hcrc.Instance = CRC;
  hcrc.Init.DefaultPolynomialUse = DEFAULT_POLYNOMIAL_ENABLE;
  hcrc.Init.DefaultInitValueUse = DEFAULT_INIT_VALUE_ENABLE;
  hcrc.Init.InputDataInversionMode = CRC_INPUTDATA_INVERSION_NONE;
  hcrc.Init.OutputDataInversionMode = CRC_OUTPUTDATA_INVERSION_DISABLE;
  hcrc.InputDataFormat = CRC_INPUTDATA_FORMAT_BYTES;
  if (HAL_CRC_Init(&hcrc) != HAL_OK)
  {
    Error_Handler();
  }

}

static void MX_DMA2D_Init(void)
{

  hdma2d.Instance = DMA2D;
  hdma2d.Init.Mode = DMA2D_R2M;
  hdma2d.Init.ColorMode = DMA2D_OUTPUT_RGB888;
  hdma2d.Init.OutputOffset = 0;
  if (HAL_DMA2D_Init(&hdma2d) != HAL_OK)
  {
    Error_Handler();
  }

}

static void MX_LTDC_Init(void)
{

  LTDC_LayerCfgTypeDef pLayerCfg = {0};

  hltdc.Instance = LTDC;
  hltdc.Init.HSPolarity = LTDC_HSPOLARITY_AL;
  hltdc.Init.VSPolarity = LTDC_VSPOLARITY_AL;
  hltdc.Init.DEPolarity = LTDC_DEPOLARITY_AL;
  hltdc.Init.PCPolarity = LTDC_PCPOLARITY_IPC;
  hltdc.Init.HorizontalSync = 40;
  hltdc.Init.VerticalSync = 9;
  hltdc.Init.AccumulatedHBP = 53;
  hltdc.Init.AccumulatedVBP = 11;
  hltdc.Init.AccumulatedActiveW = 533;
  hltdc.Init.AccumulatedActiveH = 283;
  hltdc.Init.TotalWidth = 565;
  hltdc.Init.TotalHeigh = 285;
  hltdc.Init.Backcolor.Blue = 0;
  hltdc.Init.Backcolor.Green = 0;
  hltdc.Init.Backcolor.Red = 0;
  if (HAL_LTDC_Init(&hltdc) != HAL_OK)
  {
    Error_Handler();
  }
  pLayerCfg.WindowX0 = 0;
  pLayerCfg.WindowX1 = 480;
  pLayerCfg.WindowY0 = 0;
  pLayerCfg.WindowY1 = 272;
  pLayerCfg.PixelFormat = LTDC_PIXEL_FORMAT_RGB888;
  pLayerCfg.Alpha = 255;
  pLayerCfg.Alpha0 = 0;
  pLayerCfg.BlendingFactor1 = LTDC_BLENDING_FACTOR1_CA;
  pLayerCfg.BlendingFactor2 = LTDC_BLENDING_FACTOR2_CA;
  pLayerCfg.FBStartAdress = 0x70000000;
  pLayerCfg.ImageWidth = 480;
  pLayerCfg.ImageHeight = 272;
  pLayerCfg.Backcolor.Blue = 0;
  pLayerCfg.Backcolor.Green = 0;
  pLayerCfg.Backcolor.Red = 0;
  if (HAL_LTDC_ConfigLayer(&hltdc, &pLayerCfg, 0) != HAL_OK)
  {
    Error_Handler();
  }

}

static void MX_OCTOSPI1_Init(void)
{

  /* USER CODE BEGIN OCTOSPI1_Init 0 */
  BSP_OSPI_NOR_Init_t ospi_nor_int;
  /* USER CODE END OCTOSPI1_Init 0 */

  OSPIM_CfgTypeDef sOspiManagerCfg = {0};

  /* OCTOSPI1 parameter configuration*/
  hospi1.Instance = OCTOSPI1;
  hospi1.Init.FifoThreshold = 4;
  hospi1.Init.DualQuad = HAL_OSPI_DUALQUAD_DISABLE;
  hospi1.Init.MemoryType = HAL_OSPI_MEMTYPE_MACRONIX;
  hospi1.Init.DeviceSize = 32;
  hospi1.Init.ChipSelectHighTime = 2;
  hospi1.Init.FreeRunningClock = HAL_OSPI_FREERUNCLK_DISABLE;
  hospi1.Init.ClockMode = HAL_OSPI_CLOCK_MODE_0;
  hospi1.Init.WrapSize = HAL_OSPI_WRAP_NOT_SUPPORTED;
  hospi1.Init.ClockPrescaler = 2;
  hospi1.Init.SampleShifting = HAL_OSPI_SAMPLE_SHIFTING_NONE;
  hospi1.Init.DelayHoldQuarterCycle = HAL_OSPI_DHQC_DISABLE;
  hospi1.Init.ChipSelectBoundary = 0;
  hospi1.Init.DelayBlockBypass = HAL_OSPI_DELAY_BLOCK_BYPASSED;
  hospi1.Init.MaxTran = 0;
  hospi1.Init.Refresh = 0;
  if (HAL_OSPI_Init(&hospi1) != HAL_OK)
  {
    Error_Handler();
  }
  sOspiManagerCfg.ClkPort = 1;
  sOspiManagerCfg.DQSPort = 1;
  sOspiManagerCfg.NCSPort = 1;
  sOspiManagerCfg.IOLowPort = HAL_OSPIM_IOPORT_1_LOW;
  sOspiManagerCfg.IOHighPort = HAL_OSPIM_IOPORT_1_HIGH;
  if (HAL_OSPIM_Config(&hospi1, &sOspiManagerCfg, HAL_OSPI_TIMEOUT_DEFAULT_VALUE) != HAL_OK)
  {
    Error_Handler();
  }
  /* USER CODE BEGIN OCTOSPI1_Init 2 */
  HAL_OSPI_DeInit(&hospi1);
  ospi_nor_int.InterfaceMode = BSP_OSPI_NOR_OPI_MODE;
  ospi_nor_int.TransferRate  = BSP_OSPI_NOR_DTR_TRANSFER;
  BSP_OSPI_NOR_DeInit(0);
  if(BSP_OSPI_NOR_Init(0, &ospi_nor_int) != BSP_ERROR_NONE)
  {
    Error_Handler();
  }
  if(BSP_OSPI_NOR_EnableMemoryMappedMode(0) != BSP_ERROR_NONE)
  {
    Error_Handler();
  }
  /* USER CODE END OCTOSPI1_Init 2 */

}

static void MX_OCTOSPI2_Init(void)
{

  /* USER CODE BEGIN OCTOSPI2_Init 0 */
//  BSP_OSPI_RAM_Init_t ospi_ram_init;
  /* USER CODE END OCTOSPI2_Init 0 */

  OSPIM_CfgTypeDef sOspiManagerCfg = {0};
  OSPI_HyperbusCfgTypeDef sHyperBusCfg = {0};

  /* USER CODE BEGIN OCTOSPI2_Init 1 */
  OSPI_HyperbusCmdTypeDef sCommand = {0};
  OSPI_MemoryMappedTypeDef sMemMappedCfg = {0};
  /* USER CODE END OCTOSPI2_Init 1 */
  /* OCTOSPI2 parameter configuration*/
  hospi2.Instance = OCTOSPI2;
  hospi2.Init.FifoThreshold = 4;
  hospi2.Init.DualQuad = HAL_OSPI_DUALQUAD_DISABLE;
  hospi2.Init.MemoryType = HAL_OSPI_MEMTYPE_HYPERBUS;
  hospi2.Init.DeviceSize = 24;
  hospi2.Init.ChipSelectHighTime = 4;
  hospi2.Init.FreeRunningClock = HAL_OSPI_FREERUNCLK_DISABLE;
  hospi2.Init.ClockMode = HAL_OSPI_CLOCK_MODE_0;
  hospi2.Init.WrapSize = HAL_OSPI_WRAP_NOT_SUPPORTED;
  hospi2.Init.ClockPrescaler = 2;
  hospi2.Init.SampleShifting = HAL_OSPI_SAMPLE_SHIFTING_NONE;
  hospi2.Init.DelayHoldQuarterCycle = HAL_OSPI_DHQC_ENABLE;
  hospi2.Init.ChipSelectBoundary = 23;
  hospi2.Init.DelayBlockBypass = HAL_OSPI_DELAY_BLOCK_USED;
  hospi2.Init.MaxTran = 0;
  hospi2.Init.Refresh = 400;
  if (HAL_OSPI_Init(&hospi2) != HAL_OK)
  {
    Error_Handler();
  }
  sOspiManagerCfg.ClkPort = 2;
  sOspiManagerCfg.DQSPort = 2;
  sOspiManagerCfg.NCSPort = 2;
  sOspiManagerCfg.IOLowPort = HAL_OSPIM_IOPORT_2_LOW;
  sOspiManagerCfg.IOHighPort = HAL_OSPIM_IOPORT_2_HIGH;
  if (HAL_OSPIM_Config(&hospi2, &sOspiManagerCfg, HAL_OSPI_TIMEOUT_DEFAULT_VALUE) != HAL_OK)
  {
    Error_Handler();
  }
  sHyperBusCfg.RWRecoveryTime = 3;
  sHyperBusCfg.AccessTime = 6;
  sHyperBusCfg.WriteZeroLatency = HAL_OSPI_LATENCY_ON_WRITE;
  sHyperBusCfg.LatencyMode = HAL_OSPI_FIXED_LATENCY;
  if (HAL_OSPI_HyperbusCfg(&hospi2, &sHyperBusCfg, HAL_OSPI_TIMEOUT_DEFAULT_VALUE) != HAL_OK)
  {
    Error_Handler();
  }
  /* USER CODE BEGIN OCTOSPI2_Init 2 */
  sCommand.AddressSpace = HAL_OSPI_MEMORY_ADDRESS_SPACE;
  sCommand.AddressSize  = HAL_OSPI_ADDRESS_32_BITS;
  sCommand.DQSMode      = HAL_OSPI_DQS_ENABLE;
  sCommand.Address      = 0;
  sCommand.NbData       = 1;

  if (HAL_OSPI_HyperbusCmd(&hospi2, &sCommand, HAL_OSPI_TIMEOUT_DEFAULT_VALUE) != HAL_OK)
  {
    Error_Handler();
  }

  sMemMappedCfg.TimeOutActivation = HAL_OSPI_TIMEOUT_COUNTER_DISABLE;

  if (HAL_OSPI_MemoryMapped(&hospi2, &sMemMappedCfg) != HAL_OK)
  {
    Error_Handler();
  }

  /* USER CODE END OCTOSPI2_Init 2 */

}

static void MX_RTC_Init(void)
{

  RTC_TimeTypeDef sTime = {0};
  RTC_DateTypeDef sDate = {0};

  /** Initialize RTC Only
  */
  hrtc.Instance = RTC;
  hrtc.Init.HourFormat = RTC_HOURFORMAT_24;
  hrtc.Init.AsynchPrediv = 127;
  hrtc.Init.SynchPrediv = 255;
  hrtc.Init.OutPut = RTC_OUTPUT_DISABLE;
  hrtc.Init.OutPutPolarity = RTC_OUTPUT_POLARITY_HIGH;
  hrtc.Init.OutPutType = RTC_OUTPUT_TYPE_OPENDRAIN;
  hrtc.Init.OutPutRemap = RTC_OUTPUT_REMAP_NONE;
  if (HAL_RTC_Init(&hrtc) != HAL_OK)
  {
    Error_Handler();
  }

  /** Initialize RTC and set the Time and Date
  */
  sTime.Hours = 0x0;
  sTime.Minutes = 0x0;
  sTime.Seconds = 0x0;
  sTime.DayLightSaving = RTC_DAYLIGHTSAVING_NONE;
  sTime.StoreOperation = RTC_STOREOPERATION_RESET;
  if (HAL_RTC_SetTime(&hrtc, &sTime, RTC_FORMAT_BCD) != HAL_OK)
  {
    Error_Handler();
  }
  sDate.WeekDay = RTC_WEEKDAY_MONDAY;
  sDate.Month = RTC_MONTH_JANUARY;
  sDate.Date = 0x1;
  sDate.Year = 0x0;

  if (HAL_RTC_SetDate(&hrtc, &sDate, RTC_FORMAT_BCD) != HAL_OK)
  {
    Error_Handler();
  }

}

static void MX_TIM1_Init(void)
{

  TIM_ClockConfigTypeDef sClockSourceConfig = {0};
  TIM_MasterConfigTypeDef sMasterConfig = {0};
  TIM_IC_InitTypeDef sConfigIC = {0};

  htim1.Instance = TIM1;
  htim1.Init.Prescaler = 0;
  htim1.Init.CounterMode = TIM_COUNTERMODE_UP;
  htim1.Init.Period = 65535;
  htim1.Init.ClockDivision = TIM_CLOCKDIVISION_DIV1;
  htim1.Init.RepetitionCounter = 0;
  htim1.Init.AutoReloadPreload = TIM_AUTORELOAD_PRELOAD_DISABLE;
  if (HAL_TIM_Base_Init(&htim1) != HAL_OK)
  {
    Error_Handler();
  }
  sClockSourceConfig.ClockSource = TIM_CLOCKSOURCE_INTERNAL;
  if (HAL_TIM_ConfigClockSource(&htim1, &sClockSourceConfig) != HAL_OK)
  {
    Error_Handler();
  }
  if (HAL_TIM_IC_Init(&htim1) != HAL_OK)
  {
    Error_Handler();
  }
  sMasterConfig.MasterOutputTrigger = TIM_TRGO_RESET;
  sMasterConfig.MasterOutputTrigger2 = TIM_TRGO2_RESET;
  sMasterConfig.MasterSlaveMode = TIM_MASTERSLAVEMODE_DISABLE;
  if (HAL_TIMEx_MasterConfigSynchronization(&htim1, &sMasterConfig) != HAL_OK)
  {
    Error_Handler();
  }
  sConfigIC.ICPolarity = TIM_INPUTCHANNELPOLARITY_RISING;
  sConfigIC.ICSelection = TIM_ICSELECTION_DIRECTTI;
  sConfigIC.ICPrescaler = TIM_ICPSC_DIV1;
  sConfigIC.ICFilter = 0;
  if (HAL_TIM_IC_ConfigChannel(&htim1, &sConfigIC, TIM_CHANNEL_4) != HAL_OK)
  {
    Error_Handler();
  }

}

static void MX_TIM4_Init(void)
{

  TIM_MasterConfigTypeDef sMasterConfig = {0};
  TIM_IC_InitTypeDef sConfigIC = {0};

  htim4.Instance = TIM4;
  htim4.Init.Prescaler = 0;
  htim4.Init.CounterMode = TIM_COUNTERMODE_UP;
  htim4.Init.Period = 65535;
  htim4.Init.ClockDivision = TIM_CLOCKDIVISION_DIV1;
  htim4.Init.AutoReloadPreload = TIM_AUTORELOAD_PRELOAD_DISABLE;
  if (HAL_TIM_IC_Init(&htim4) != HAL_OK)
  {
    Error_Handler();
  }
  sMasterConfig.MasterOutputTrigger = TIM_TRGO_RESET;
  sMasterConfig.MasterSlaveMode = TIM_MASTERSLAVEMODE_DISABLE;
  if (HAL_TIMEx_MasterConfigSynchronization(&htim4, &sMasterConfig) != HAL_OK)
  {
    Error_Handler();
  }
  sConfigIC.ICPolarity = TIM_INPUTCHANNELPOLARITY_RISING;
  sConfigIC.ICSelection = TIM_ICSELECTION_DIRECTTI;
  sConfigIC.ICPrescaler = TIM_ICPSC_DIV1;
  sConfigIC.ICFilter = 0;
  if (HAL_TIM_IC_ConfigChannel(&htim4, &sConfigIC, TIM_CHANNEL_4) != HAL_OK)
  {
    Error_Handler();
  }

}

static void MX_USART3_UART_Init(void)
{

  huart3.Instance = USART3;
  huart3.Init.BaudRate = 115200;
  huart3.Init.WordLength = UART_WORDLENGTH_8B;
  huart3.Init.StopBits = UART_STOPBITS_1;
  huart3.Init.Parity = UART_PARITY_NONE;
  huart3.Init.Mode = UART_MODE_TX_RX;
  huart3.Init.HwFlowCtl = UART_HWCONTROL_NONE;
  huart3.Init.OverSampling = UART_OVERSAMPLING_16;
  huart3.Init.OneBitSampling = UART_ONE_BIT_SAMPLE_DISABLE;
  huart3.Init.ClockPrescaler = UART_PRESCALER_DIV1;
  huart3.AdvancedInit.AdvFeatureInit = UART_ADVFEATURE_NO_INIT;
  if (HAL_UART_Init(&huart3) != HAL_OK)
  {
    Error_Handler();
  }
  if (HAL_UARTEx_SetTxFifoThreshold(&huart3, UART_TXFIFO_THRESHOLD_1_8) != HAL_OK)
  {
    Error_Handler();
  }
  if (HAL_UARTEx_SetRxFifoThreshold(&huart3, UART_RXFIFO_THRESHOLD_1_8) != HAL_OK)
  {
    Error_Handler();
  }
  if (HAL_UARTEx_DisableFifoMode(&huart3) != HAL_OK)
  {
    Error_Handler();
  }

}

static void MX_WWDG1_Init(void)
{

  hwwdg1.Instance = WWDG1;
  hwwdg1.Init.Prescaler = WWDG_PRESCALER_128;
  hwwdg1.Init.Window = 0x50;
  hwwdg1.Init.Counter = 0x7F;
  hwwdg1.Init.EWIMode = WWDG_EWI_DISABLE;
  if (HAL_WWDG_Init(&hwwdg1) != HAL_OK)
  {
    Error_Handler();
  }
  /* USER CODE BEGIN WWDG1_Init 2 */
}

/* USER CODE BEGIN WWDG1_Init 2 */
uint32_t TimeoutCalculation(uint32_t timevalue)
{
      uint32_t timeoutvalue = 0;
      uint32_t pclk1 = 0;
      uint32_t wdgtb = 0;

      /* Get PCLK1 value */
      pclk1 = HAL_RCC_GetPCLK1Freq();

      /* get prescaler */
      switch(hwwdg1.Init.Prescaler)
      {
        case WWDG_PRESCALER_1:   wdgtb = 1;   break;
        case WWDG_PRESCALER_2:   wdgtb = 2;   break;
        case WWDG_PRESCALER_4:   wdgtb = 4;   break;
        case WWDG_PRESCALER_8:   wdgtb = 8;   break;
        case WWDG_PRESCALER_16:  wdgtb = 16;  break;
        case WWDG_PRESCALER_32:  wdgtb = 32;  break;
        case WWDG_PRESCALER_64:  wdgtb = 64;  break;
        case WWDG_PRESCALER_128: wdgtb = 128; break;

        default: Error_Handler(); break;
      }

      /* calculate timeout */
      timeoutvalue = ((4096 * wdgtb * timevalue) / (pclk1 / 1000));

      return timeoutvalue;
  /* USER CODE END WWDG1_Init 2 */

}

static void MX_GPIO_Init(void)
{
  GPIO_InitTypeDef GPIO_InitStruct = {0};

  /* GPIO Ports Clock Enable */
  __HAL_RCC_GPIOB_CLK_ENABLE();
  __HAL_RCC_GPIOG_CLK_ENABLE();
  __HAL_RCC_GPIOD_CLK_ENABLE();
  __HAL_RCC_GPIOE_CLK_ENABLE();
  __HAL_RCC_GPIOA_CLK_ENABLE();
  __HAL_RCC_GPIOC_CLK_ENABLE();
  __HAL_RCC_GPIOH_CLK_ENABLE();
  __HAL_RCC_GPIOF_CLK_ENABLE();

  /*Configure GPIO pin Output Level */
  HAL_GPIO_WritePin(GPIOG, LCD_BL_CTRL_Pin|RENDER_TIME_Pin, GPIO_PIN_RESET);

  /*Configure GPIO pin Output Level */
  HAL_GPIO_WritePin(GPIOB, MCU_ACTIVE_Pin|FRAME_RATE_Pin, GPIO_PIN_RESET);

  /*Configure GPIO pin Output Level */
  HAL_GPIO_WritePin(LCD_DISP_GPIO_Port, LCD_DISP_Pin, GPIO_PIN_RESET);

  /*Configure GPIO pin Output Level */
  HAL_GPIO_WritePin(VSYNC_FREQ_GPIO_Port, VSYNC_FREQ_Pin, GPIO_PIN_RESET);

  /*Configure GPIO pin : Mode_Pin */
  GPIO_InitStruct.Pin = Mode_Pin;
  GPIO_InitStruct.Mode = GPIO_MODE_INPUT;
  GPIO_InitStruct.Pull = GPIO_PULLUP;
  HAL_GPIO_Init(Mode_GPIO_Port, &GPIO_InitStruct);

  /*Configure GPIO pin : Switch_Fuel_Pin */
  GPIO_InitStruct.Pin = Switch_Fuel_Pin;
  GPIO_InitStruct.Mode = GPIO_MODE_INPUT;
  GPIO_InitStruct.Pull = GPIO_PULLDOWN;
  HAL_GPIO_Init(Switch_Fuel_GPIO_Port, &GPIO_InitStruct);

  /*Configure GPIO pin : LCD_BL_CTRL_Pin */
  GPIO_InitStruct.Pin = LCD_BL_CTRL_Pin;
  GPIO_InitStruct.Mode = GPIO_MODE_OUTPUT_PP;
  GPIO_InitStruct.Pull = GPIO_NOPULL;
  GPIO_InitStruct.Speed = GPIO_SPEED_FREQ_LOW;
  HAL_GPIO_Init(LCD_BL_CTRL_GPIO_Port, &GPIO_InitStruct);

  /*Configure GPIO pin : Reset_Pin */
  GPIO_InitStruct.Pin = Reset_Pin;
  GPIO_InitStruct.Mode = GPIO_MODE_INPUT;
  GPIO_InitStruct.Pull = GPIO_PULLUP;
  HAL_GPIO_Init(Reset_GPIO_Port, &GPIO_InitStruct);

  /*Configure GPIO pin : PF6 */
  GPIO_InitStruct.Pin = GPIO_PIN_6;
  GPIO_InitStruct.Mode = GPIO_MODE_AF_PP;
  GPIO_InitStruct.Pull = GPIO_NOPULL;
  GPIO_InitStruct.Speed = GPIO_SPEED_FREQ_LOW;
  GPIO_InitStruct.Alternate = GPIO_AF2_FDCAN3;
  HAL_GPIO_Init(GPIOF, &GPIO_InitStruct);

  /*Configure GPIO pin : RENDER_TIME_Pin */
  GPIO_InitStruct.Pin = RENDER_TIME_Pin;
  GPIO_InitStruct.Mode = GPIO_MODE_OUTPUT_PP;
  GPIO_InitStruct.Pull = GPIO_NOPULL;
  GPIO_InitStruct.Speed = GPIO_SPEED_FREQ_VERY_HIGH;
  HAL_GPIO_Init(RENDER_TIME_GPIO_Port, &GPIO_InitStruct);

  /*Configure GPIO pin : Ignition_Pin */
  GPIO_InitStruct.Pin = Ignition_Pin;
  GPIO_InitStruct.Mode = GPIO_MODE_INPUT;
  GPIO_InitStruct.Pull = GPIO_PULLUP;
  HAL_GPIO_Init(Ignition_GPIO_Port, &GPIO_InitStruct);

  /*Configure GPIO pins : MCU_ACTIVE_Pin FRAME_RATE_Pin */
  GPIO_InitStruct.Pin = MCU_ACTIVE_Pin|FRAME_RATE_Pin;
  GPIO_InitStruct.Mode = GPIO_MODE_OUTPUT_PP;
  GPIO_InitStruct.Pull = GPIO_NOPULL;
  GPIO_InitStruct.Speed = GPIO_SPEED_FREQ_VERY_HIGH;
  HAL_GPIO_Init(GPIOB, &GPIO_InitStruct);

  /*Configure GPIO pin : LCD_DISP_Pin */
  GPIO_InitStruct.Pin = LCD_DISP_Pin;
  GPIO_InitStruct.Mode = GPIO_MODE_OUTPUT_PP;
  GPIO_InitStruct.Pull = GPIO_NOPULL;
  GPIO_InitStruct.Speed = GPIO_SPEED_FREQ_LOW;
  HAL_GPIO_Init(LCD_DISP_GPIO_Port, &GPIO_InitStruct);

  /*Configure GPIO pin : VSYNC_FREQ_Pin */
  GPIO_InitStruct.Pin = VSYNC_FREQ_Pin;
  GPIO_InitStruct.Mode = GPIO_MODE_OUTPUT_PP;
  GPIO_InitStruct.Pull = GPIO_NOPULL;
  GPIO_InitStruct.Speed = GPIO_SPEED_FREQ_VERY_HIGH;
  HAL_GPIO_Init(VSYNC_FREQ_GPIO_Port, &GPIO_InitStruct);

}

/* USER CODE BEGIN 4 */

void Disp_imgDataHyperRAM_Init(void)
{
	memset(ucImage_image_HypRam,0,(32640*12));
	memset(ucImage_fuel_red_HypRAM,0,(160*12));
#if 1
	uint32_t Address1 = (uint32_t)(&image_image_const[0] - FLASH_BASE_ADDR);
	if(BSP_OSPI_NOR_Read(BSP_INSTANCE,ucImage_image_HypRam, Address1, (32640*12)))
	{
		printf("Copy Fail-1\n\r");
	}
	else
	{
		printf("Copy Success1\n\r");
	}
	uint32_t Address2 = (uint32_t)(&image_fuel_red_const[0] - FLASH_BASE_ADDR);
	if(BSP_OSPI_NOR_Read(BSP_INSTANCE,ucImage_image_HypRam, Address2, (160*12)))
	{
		printf("Copy Fail-2\n\r");
	}
	else
	{
		printf("Copy Success2\n\r");
	}
#else
	memcpy(ucImage_image_HypRam,image_image_const,(32640*12));
	if(memcmp(image_image_const,ucImage_image_HypRam,(32640*12))!=0)
	{
		printf("ucImage_image_HypRam,Verification Failed\n\r");
	}
	else
	{
		printf("ucImage_image_HypRam,Verification Passed\n\r");
	}

	memcpy(ucImage_fuel_red_HypRAM,image_fuel_red_const,(160*12));
	if(memcmp(image_fuel_red_const,ucImage_fuel_red_HypRAM,(160*12))!=0)
	{
		printf("ucImage_fuel_red_HypRAM, Verification Failed\n\r");
	}
	else
	{
		printf("ucImage_fuel_red_HypRAM, Verification Passed\n\r");
	}
#endif
}
/* USER CODE END 4 */

void StartDefaultTask(void *argument)
{
  /* USER CODE BEGIN 5 */
  /* Infinite loop */
	//delay = TimeoutCalculation((WwdgHandle.Init.Counter - WwdgHandle.Init.Window) + 1) + 1;
  for(;;)
  {
    osDelay(100);
  }
  /* USER CODE END 5 */
}

void WDG_SRVC_Task(void *argument)
{
  /* USER CODE BEGIN WDG_SRVC_Task */
	uint32_t delay=0;
	delay = TimeoutCalculation((hwwdg1.Init.Counter - hwwdg1.Init.Window) + 1) + 1;
  for(;;)
  {
    osDelay(delay); //watchdog period
    //service or refresh or reload the watchdog here

    if (HAL_WWDG_Refresh(&hwwdg1) != HAL_OK)
    {
          Error_Handler();
    }

  }
  /* USER CODE END WDG_SRVC_Task */
}

void DigitalDebounce_Task(void *argument)
{
  /* USER CODE BEGIN DigitalDebounce_Task */
//	vEE_Demo();
//	Disp_imgDataHyperRAM_Init();
  /* Infinite loop */
  for(;;)
  {
	DebounceTask();
	//get_debounce_status();
	osDelay(4);
  }
  /* USER CODE END DigitalDebounce_Task */
}

void State_Machine(void *argument)
{
  /* USER CODE BEGIN State_Machine */
  /* Infinite loop */
  for(;;)
  {
      State_Manager_task();
      //IGN_get_current_state();
      osDelay(50);
  }
  /* USER CODE END State_Machine */
}

void Odo_Task(void *argument)
{
  /* USER CODE BEGIN Odo_Task */
  /* Infinite loop */
  for(;;)
  {
	  vOdoAlgorithm();
    osDelay(5000);
  }
  /* USER CODE END Odo_Task */
}

void speedo_Task(void *argument)
{
  /* USER CODE BEGIN speedo_Task */
  /* Infinite loop */
  for(;;)
  {
	vSpeedoAlgorithm();
    osDelay(5000);
  }
  /* USER CODE END speedo_Task */
}

void Tacho_Task(void *argument)
{
  /* USER CODE BEGIN Tacho_Task */
  /* Infinite loop */
  for(;;)
  {
	  vTacho_App();
    osDelay(5000);
  }
  /* USER CODE END Tacho_Task */
}

 /* MPU Configuration */

void MPU_Config(void)
{
  MPU_Region_InitTypeDef MPU_InitStruct = {0};

  /* Disables the MPU */
  HAL_MPU_Disable();
#if 0
  /** Initializes and configures the Region and the memory to be protected
  */
  MPU_InitStruct.Enable = MPU_REGION_ENABLE;
  MPU_InitStruct.Number = MPU_REGION_NUMBER0;
  MPU_InitStruct.BaseAddress = 0x0;
  MPU_InitStruct.Size = MPU_REGION_SIZE_4GB;
  MPU_InitStruct.SubRegionDisable = 0x87;
  MPU_InitStruct.TypeExtField = MPU_TEX_LEVEL0;
  MPU_InitStruct.AccessPermission = MPU_REGION_NO_ACCESS;
  MPU_InitStruct.DisableExec = MPU_INSTRUCTION_ACCESS_DISABLE;
  MPU_InitStruct.IsShareable = MPU_ACCESS_SHAREABLE;
  MPU_InitStruct.IsCacheable = MPU_ACCESS_NOT_CACHEABLE;
  MPU_InitStruct.IsBufferable = MPU_ACCESS_NOT_BUFFERABLE;

  HAL_MPU_ConfigRegion(&MPU_InitStruct);

  /* Configure the MPU attributes as WT for OCTOSPI1 */
  MPU_InitStruct.Enable = MPU_REGION_ENABLE;
  MPU_InitStruct.BaseAddress = OCTOSPI1_BASE;
  MPU_InitStruct.Size = MPU_REGION_SIZE_64MB;
  MPU_InitStruct.AccessPermission = MPU_REGION_FULL_ACCESS;
  MPU_InitStruct.IsBufferable = MPU_ACCESS_BUFFERABLE;
  MPU_InitStruct.IsCacheable = MPU_ACCESS_CACHEABLE;
  MPU_InitStruct.IsShareable = MPU_ACCESS_SHAREABLE;
  MPU_InitStruct.Number = MPU_REGION_NUMBER1;
  MPU_InitStruct.TypeExtField = MPU_TEX_LEVEL1;
  MPU_InitStruct.SubRegionDisable = 0x00;
  MPU_InitStruct.DisableExec = MPU_INSTRUCTION_ACCESS_ENABLE;

  HAL_MPU_ConfigRegion(&MPU_InitStruct);
#endif
  /* Configure the MPU attributes as WT for OCTOSPI2 */
  MPU_InitStruct.Enable = MPU_REGION_ENABLE;
  MPU_InitStruct.BaseAddress = OCTOSPI2_BASE;
  MPU_InitStruct.Size = MPU_REGION_SIZE_128MB;
  MPU_InitStruct.AccessPermission = MPU_REGION_FULL_ACCESS;
  MPU_InitStruct.IsBufferable = MPU_ACCESS_BUFFERABLE;
  MPU_InitStruct.IsCacheable = MPU_ACCESS_CACHEABLE;
  MPU_InitStruct.IsShareable = MPU_ACCESS_SHAREABLE;
  MPU_InitStruct.Number = MPU_REGION_NUMBER1;
  MPU_InitStruct.TypeExtField = MPU_TEX_LEVEL1;
  MPU_InitStruct.SubRegionDisable = 0x00;
  MPU_InitStruct.DisableExec = MPU_INSTRUCTION_ACCESS_ENABLE;

  HAL_MPU_ConfigRegion(&MPU_InitStruct);
  /* Enables the MPU */
  HAL_MPU_Enable(MPU_PRIVILEGED_DEFAULT);

}

void HAL_TIM_PeriodElapsedCallback(TIM_HandleTypeDef *htim)
{
  if (htim->Instance == TIM6) {
    HAL_IncTick();
  }
}

void Error_Handler(void)
{
  /* USER CODE BEGIN Error_Handler_Debug */
  /* User can add his own implementation to report the HAL error return state */
	uint8_t counter = 0;
	counter++;
  /* USER CODE END Error_Handler_Debug */
}
